# APM32F423 register map
File version: 1.0
CPU: CM4 r1p0, little endian, no MPU, no FPU, 4 interrupt priority bits
Registers are 32-bit, read-write, reset 0x0 unless marked. A register's access mark holds for its fields unless they carry their own. Offsets are from the block's base; [hi:lo] are bit positions; lines under a group give offsets from that group; {n}, {i} and the like mark numbered series.

## ADC1 — Analog-to-digital converter
Base 0x40012000
Same registers: ADC2 0x40012100, ADC3 0x40012200
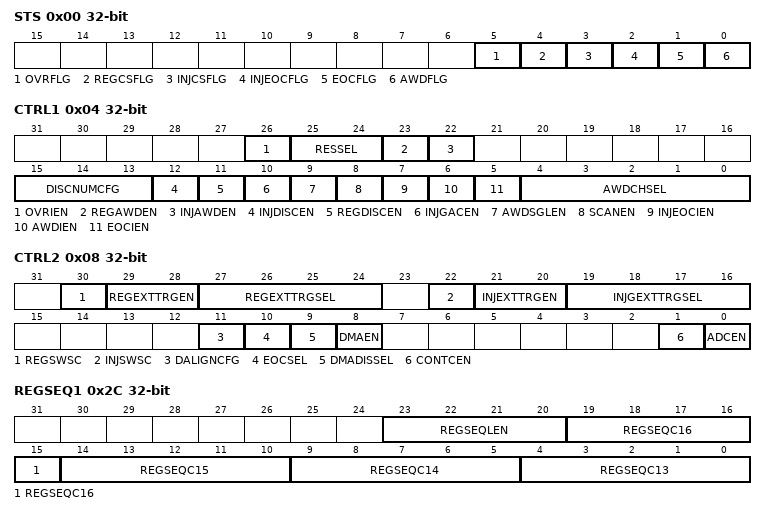
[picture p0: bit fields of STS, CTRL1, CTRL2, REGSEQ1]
0x00 STS — status register
  [5] OVRFLG — Overrun
  [4] REGCSFLG — Regular channel start flag
  [3] INJCSFLG — Injected channel start flag
  [2] INJEOCFLG — Injected channel end of conversion
  [1] EOCFLG — Regular channel end of conversion
  [0] AWDFLG — Analog watchdog flag
0x04 CTRL1 — control register 1
  [26] OVRIEN — Overrun interrupt enable
  [25:24] RESSEL — Resolution
  [23] REGAWDEN — Analog watchdog enable on regular channels
  [22] INJAWDEN — Analog watchdog enable on injected channels
  [15:13] DISCNUMCFG — Discontinuous mode channel count
  [12] INJDISCEN — Discontinuous mode on injected channels
  [11] REGDISCEN — Discontinuous mode on regular channels
  [10] INJGACEN — Automatic injected group conversion
  [9] AWDSGLEN — Enable the watchdog on a single channel in scan mode
  [8] SCANEN — Scan mode
  [7] INJEOCIEN — Interrupt enable for injected channels
  [6] AWDIEN — Analog watchdog interrupt enable
  [5] EOCIEN — Interrupt enable for EOC
  [4:0] AWDCHSEL — Analog watchdog channel select bits
0x08 CTRL2 — control register 2
  [30] REGSWSC — Start conversion of regular channels
  [29:28] REGEXTTRGEN — External trigger enable for regular channels
  [27:24] REGEXTTRGSEL — External event select for regular group
  [22] INJSWSC — Start conversion of injected channels
  [21:20] INJEXTTRGEN — External trigger enable for injected channels
  [19:16] INJGEXTTRGSEL — External event select for injected group
  [11] DALIGNCFG — Data alignment
  [10] EOCSEL — End of conversion selection
  [9] DMADISSEL — DMA disable selection (for single ADC mode)
  [8] DMAEN — Direct memory access mode (for single ADC mode)
  [1] CONTCEN — Continuous conversion
  [0] ADCEN — A/D Converter ON / OFF
0x0C SMPTIM1 — sample time register 1
  [31:0] SMPCYCCFG1 — Sample time bits
0x10 SMPTIM2 — sample time register 2
  [31:0] SMPCYCCFG2 — Sample time bits
{0x10+4i} INJDOF{i} (i=1..4) — injected channel data offset register {i}
  [11:0] INJDOF{i} — Data offset for injected channel {i}
0x24 AWDHT reset 0xFFF — watchdog higher threshold register
  [11:0] AWDHT — Analog watchdog higher threshold
0x28 AWDLT — watchdog lower threshold register
  [11:0] AWDLT — Analog watchdog lower threshold
0x2C REGSEQ1 — regular sequence register 1
  [23:20] REGSEQLEN — Regular channel sequence length
  [5n-61:5n-65] REGSEQC{n} (n=13..16) — {n}th conversion in regular sequence
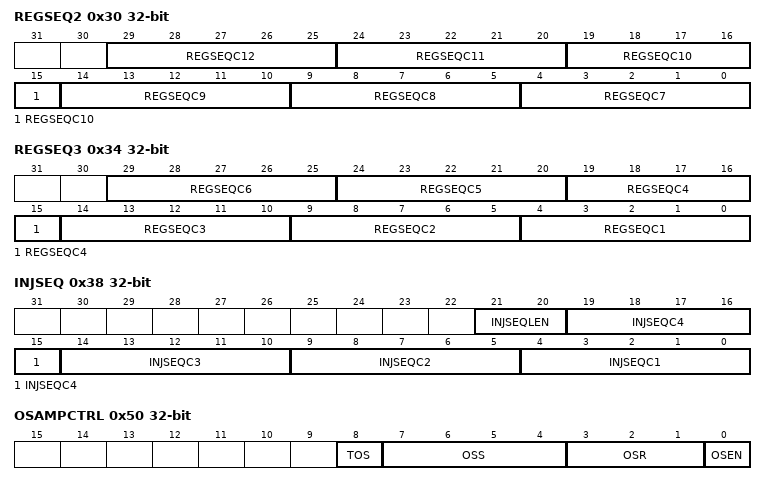
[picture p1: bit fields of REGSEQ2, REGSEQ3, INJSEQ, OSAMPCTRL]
0x30 REGSEQ2 — regular sequence register 2
  [5n-31:5n-35] REGSEQC{n} (n=7..12) — {n}th conversion in regular sequence
0x34 REGSEQ3 — regular sequence register 3
  [29:25] REGSEQC6 — 6th conversion in regular sequence
  [24:20] REGSEQC5 — 5th conversion in regular sequence
  [19:15] REGSEQC4 — 4th conversion in regular sequence
  [14:10] REGSEQC3 — 3rd conversion in regular sequence
  [9:5] REGSEQC2 — 2nd conversion in regular sequence
  [4:0] REGSEQC1 — 1st conversion in regular sequence
0x38 INJSEQ — injected sequence register
  [21:20] INJSEQLEN — Injected sequence length
  [19:15] INJSEQC4 — 4th conversion in injected sequence
  [14:10] INJSEQC3 — 3rd conversion in injected sequence
  [9:5] INJSEQC2 — 2nd conversion in injected sequence
  [4:0] INJSEQC1 — 1st conversion in injected sequence
{0x38+4i} INJDATA{i} ro (i=1..4) — injected data register x
  [15:0] INJDATA — Injected data
0x4C REGDATA ro — regular data register
  [15:0] REGDATA — Regular data
0x50 OSAMPCTRL — oversampling register
  [8] TOS — oversampling trigger
  [7:4] OSS — oversampling shift
  [3:1] OSR — oversampling rate
  [0] OSEN — oversampling enabled

## USART6 — Universal synchronous asynchronous receiver transmitter
Base 0x40011400
Same registers: USART2 0x40004400, USART3 0x40004800, USART1 0x40011000
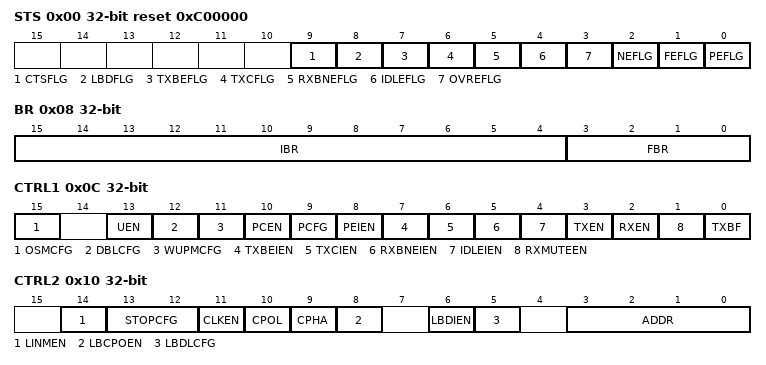
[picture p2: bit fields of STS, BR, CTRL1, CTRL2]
0x00 STS access per field reset 0xC00000 — Status register
  [9] CTSFLG rw — CTS flag
  [8] LBDFLG rw — LIN break detection flag
  [7] TXBEFLG ro — Transmit data register empty
  [6] TXCFLG rw — Transmission complete
  [5] RXBNEFLG rw — Read data register not empty
  [4] IDLEFLG ro — IDLE line detected
  [3] OVREFLG ro — Overrun error
  [2] NEFLG ro — Noise detected flag
  [1] FEFLG ro — Framing error
  [0] PEFLG ro — Parity error
0x04 DATA
  [8:0] DATA — Data value
0x08 BR — Baud rate register
  [15:4] IBR — mantissa of USARTDIV
  [3:0] FBR — fraction of USARTDIV
0x0C CTRL1 — Control register 1
  [15] OSMCFG — Oversampling mode
  [13] UEN — USART enable
  [12] DBLCFG — Word length
  [11] WUPMCFG — Wakeup method
  [10] PCEN — Parity control enable
  [9] PCFG — Parity selection
  [8] PEIEN — Parity Error Interrupt Enable
  [7] TXBEIEN — Transmit Buffer Empty Interrupt Enable
  [6] TXCIEN — Transmission complete interrupt enable
  [5] RXBNEIEN — RXNE interrupt enable
  [4] IDLEIEN — IDLE interrupt enable
  [3] TXEN — Transmitter enable
  [2] RXEN — Receiver enable
  [1] RXMUTEEN — Receiver wakeup
  [0] TXBF — Send break
0x10 CTRL2 — Control register 2
  [14] LINMEN — LIN mode enable
  [13:12] STOPCFG — STOP bits
  [11] CLKEN — Clock enable
  [10] CPOL — Clock polarity
  [9] CPHA — Clock phase
  [8] LBCPOEN — Last bit clock pulse
  [6] LBDIEN — LIN break detection interrupt enable
  [5] LBDLCFG — lin break detection length
  [3:0] ADDR — Address of the USART node
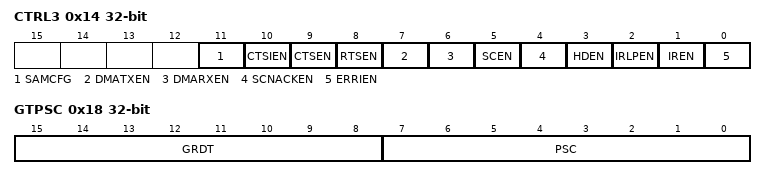
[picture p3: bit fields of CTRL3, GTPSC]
0x14 CTRL3 — Control register 3
  [11] SAMCFG — One sample bit method enable
  [10] CTSIEN — CTS interrupt enable
  [9] CTSEN — CTS enable
  [8] RTSEN — RTS enable
  [7] DMATXEN — DMA enable transmitter
  [6] DMARXEN — DMA enable receiver
  [5] SCEN — Smartcard mode enable
  [4] SCNACKEN — Smartcard NACK enable
  [3] HDEN — Half-duplex selection
  [2] IRLPEN — IrDA low-power
  [1] IREN — IrDA mode enable
  [0] ERRIEN — Error interrupt enable
0x18 GTPSC — Guard time and prescaler register
  [15:8] GRDT — Guard time value
  [7:0] PSC — Prescaler value
